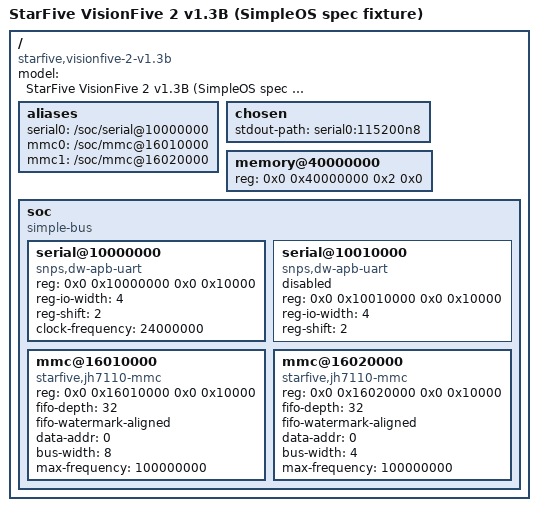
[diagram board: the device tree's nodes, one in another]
// Minimal StarFive JH7110 / VisionFive 2 device tree for host-side specs.
//
// Hand-written for SimpleOS (not copied from any vendor tree). It carries only
// the facts the riscv64 kernel consumes, with the board's real values:
//   * stdout-path through the serial0 alias, as VisionFive 2 firmware sets it;
//   * UART0 = Synopsys DesignWare APB 8250 at 0x10000000, reg-shift 2,
//     reg-io-width 4 (live MMIO on a VF2 confirmed 32-bit access / shift 2,
//     doc/01_research/local/starfive_visionfive2_simpleos.md);
//   * DRAM base 0x40000000 (8 GiB board);
//   * the two DW MSHC SDIO controllers: mmc@16010000 (eMMC slot, bus-width 8)
//     and mmc@16020000 (micro-SD slot, bus-width 4), fifo-depth 32,
//     data-addr 0 (= no override; FIFO window chosen by VERID).
// Rebuild: dtc -I dts -O dtb -o jh7110_visionfive2_min.dtb jh7110_visionfive2_min.dts
/dts-v1/;

/ {
	#address-cells = <2>;
	#size-cells = <2>;
	compatible = "starfive,visionfive-2-v1.3b", "starfive,jh7110";
	model = "StarFive VisionFive 2 v1.3B (SimpleOS spec fixture)";

	aliases {
		serial0 = "/soc/serial@10000000";
		mmc0 = "/soc/mmc@16010000";
		mmc1 = "/soc/mmc@16020000";
	};

	chosen {
		stdout-path = "serial0:115200n8";
	};

	memory@40000000 {
		device_type = "memory";
		reg = <0x0 0x40000000 0x2 0x0>;
	};

	soc {
		compatible = "simple-bus";
		#address-cells = <2>;
		#size-cells = <2>;
		ranges;

		serial@10000000 {
			compatible = "snps,dw-apb-uart";
			reg = <0x0 0x10000000 0x0 0x10000>;
			reg-io-width = <4>;
			reg-shift = <2>;
			clock-frequency = <24000000>;
			status = "okay";
		};

		serial@10010000 {
			compatible = "snps,dw-apb-uart";
			reg = <0x0 0x10010000 0x0 0x10000>;
			reg-io-width = <4>;
			reg-shift = <2>;
			status = "disabled";
		};

		mmc@16010000 {
			compatible = "starfive,jh7110-mmc";
			reg = <0x0 0x16010000 0x0 0x10000>;
			fifo-depth = <32>;
			fifo-watermark-aligned;
			data-addr = <0>;
			bus-width = <8>;
			max-frequency = <100000000>;
			status = "okay";
		};

		mmc@16020000 {
			compatible = "starfive,jh7110-mmc";
			reg = <0x0 0x16020000 0x0 0x10000>;
			fifo-depth = <32>;
			fifo-watermark-aligned;
			data-addr = <0>;
			bus-width = <4>;
			max-frequency = <100000000>;
			status = "okay";
		};
	};
};
